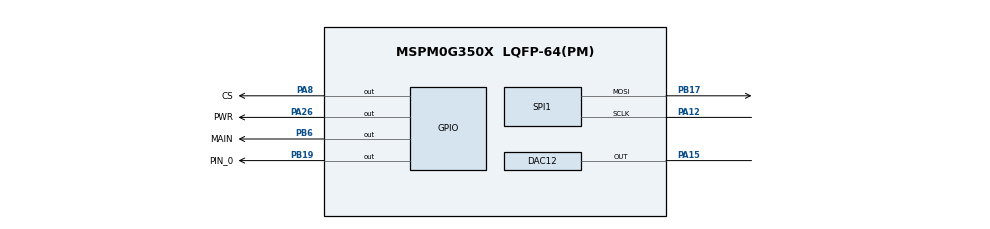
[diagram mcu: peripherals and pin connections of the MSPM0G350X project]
/**
 * @cliArgs --device "MSPM0G350X" --part "Default" --package "LQFP-64(PM)" --product "mspm0_sdk@2.10.00.04"
 * @versions {"tool":"1.26.2+4477"}
 */

/**
 * Import the modules used in this configuration.
 */
const ADC12         = scripting.addModule("/ti/driverlib/ADC12", {}, false);
const ADC121        = ADC12.addInstance();
const DAC12         = scripting.addModule("/ti/driverlib/DAC12");
const GPIO          = scripting.addModule("/ti/driverlib/GPIO", {}, false);
const GPIO1         = GPIO.addInstance();
const GPIO2         = GPIO.addInstance();
const GPIO3         = GPIO.addInstance();
const GPIO4         = GPIO.addInstance();
const GPIO5         = GPIO.addInstance();
const SPI           = scripting.addModule("/ti/driverlib/SPI", {}, false);
const SPI1          = SPI.addInstance();
const SYSCTL        = scripting.addModule("/ti/driverlib/SYSCTL");
const TIMER         = scripting.addModule("/ti/driverlib/TIMER", {}, false);
const TIMER1        = TIMER.addInstance();
const ProjectConfig = scripting.addModule("/ti/project_config/ProjectConfig");

/**
 * Write custom configuration values to the imported modules.
 */
ADC121.$name               = "AUDIO_ADC";
ADC121.trigSrc             = "DL_ADC12_TRIG_SRC_EVENT";
ADC121.subChanID           = 1;
ADC121.adcMem0_name        = "ADC_MEM0";
ADC121.adcMem0chansel      = "DL_ADC12_INPUT_CHAN_5";
ADC121.enabledInterrupts   = ["DL_ADC12_INTERRUPT_MEM0_RESULT_LOADED"];
ADC121.repeatMode          = true;
ADC121.powerDownMode       = "DL_ADC12_POWER_DOWN_MODE_MANUAL";
ADC121.sampleTime0         = "25us";
ADC121.peripheral.$assign  = "ADC0";
ADC121.adcPin5Config.$name = "ti_driverlib_gpio_GPIOPinGeneric2";

const Board = scripting.addModule("/ti/driverlib/Board", {}, false);

DAC12.dacOutputPinEn            = true;
DAC12.pubChanID                 = 4;
DAC12.dacAmplifier              = "ON";
DAC12.dacOutput12               = 2048;
DAC12.peripheral.$assign        = "DAC0";
DAC12.peripheral.OutPin.$assign = "PA15";
DAC12.OutPinConfig.$name        = "ti_driverlib_gpio_GPIOPinGeneric3";

GPIO1.$name                         = "AMP_CONTROL";
GPIO1.port                          = "PORTB";
GPIO1.associatedPins[0].$name       = "MAIN";
GPIO1.associatedPins[0].ioStructure = "SD";
GPIO1.associatedPins[0].pin.$assign = "PB6";

GPIO2.port                                = "PORTB";
GPIO2.portSegment                         = "Upper";
GPIO2.$name                               = "USER_LED";
GPIO2.associatedPins[0].$name             = "BLUE";
GPIO2.associatedPins[0].launchPadShortcut = "LED2BlueEn";

GPIO3.$name                          = "MICROPHONE";
GPIO3.port                           = "PORTA";
GPIO3.associatedPins[0].initialValue = "SET";
GPIO3.associatedPins[0].ioStructure  = "SD";
GPIO3.associatedPins[0].$name        = "PWR";
GPIO3.associatedPins[0].pin.$assign  = "PA26";

GPIO4.$name                         = "DATA_COMMAND";
GPIO4.port                          = "PORTB";
GPIO4.associatedPins[0].$name       = "PIN_0";
GPIO4.associatedPins[0].pin.$assign = "PB19";

GPIO5.port                           = "PORTA";
GPIO5.$name                          = "TFT_SELECT";
GPIO5.associatedPins[0].$name        = "CS";
GPIO5.associatedPins[0].initialValue = "SET";
GPIO5.associatedPins[0].pin.$assign  = "PA8";

SPI1.$name                              = "SPI_LED";
SPI1.chipSelect                         = [];
SPI1.direction                          = "PICO";
SPI1.frameFormat                        = "MOTO3";
SPI1.targetBitRate                      = 16000000;
SPI1.sclkPinConfig.direction            = scripting.forceWrite("OUTPUT");
SPI1.sclkPinConfig.onlyInternalResistor = scripting.forceWrite(false);
SPI1.sclkPinConfig.passedPeripheralType = scripting.forceWrite("Digital");
SPI1.sclkPinConfig.$name                = "ti_driverlib_gpio_GPIOPinGeneric0";
SPI1.mosiPinConfig.direction            = scripting.forceWrite("OUTPUT");
SPI1.mosiPinConfig.hideOutputInversion  = scripting.forceWrite(false);
SPI1.mosiPinConfig.onlyInternalResistor = scripting.forceWrite(false);
SPI1.mosiPinConfig.passedPeripheralType = scripting.forceWrite("Digital");
SPI1.mosiPinConfig.$name                = "ti_driverlib_gpio_GPIOPinGeneric1";
SPI1.peripheral.$assign                 = "SPI0";
SPI1.peripheral.sclkPin.$assign         = "PA12";
SPI1.peripheral.mosiPin.$assign         = "PB17";

SYSCTL.forceDefaultClkConfig = true;
SYSCTL.MFPCLKEn              = true;

TIMER1.$name                       = "ADC_SAMPLE_TIMER";
TIMER1.timerMode                   = "PERIODIC";
TIMER1.event1PublisherChannel      = 1;
TIMER1.event1ControllerInterruptEn = ["ZERO_EVENT"];
TIMER1.subscriberChannel           = 5;
TIMER1.timerPeriod                 = "5e-5";
TIMER1.peripheral.$assign          = "TIMA1";

ProjectConfig.genLibCMSIS = true;

/**
 * Pinmux solution for unlocked pins/peripherals. This ensures that minor changes to the automatic solver in a future
 * version of the tool will not impact the pinmux you originally saw.  These lines can be completely deleted in order to
 * re-solve from scratch.
 */
ADC121.peripheral.adcPin5.$suggestSolution   = "PB24";
Board.peripheral.$suggestSolution            = "DEBUGSS";
Board.peripheral.swclkPin.$suggestSolution   = "PA20";
Board.peripheral.swdioPin.$suggestSolution   = "PA19";
GPIO2.associatedPins[0].pin.$suggestSolution = "PB22";
SYSCTL.peripheral.$suggestSolution           = "SYSCTL";
